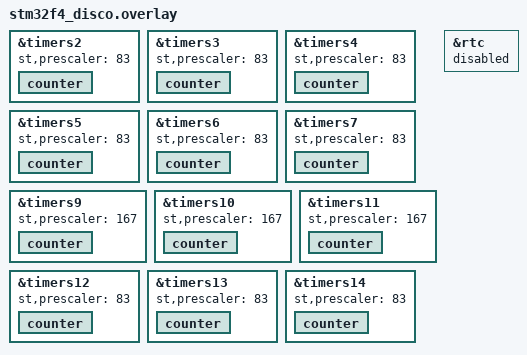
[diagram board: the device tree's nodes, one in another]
/*
 * Copyright (c) 2025 STMicroelectronics
 *
 * SPDX-License-Identifier: Apache-2.0
 */

&timers2 {
	st,prescaler = <83>;
	status = "okay";

	counter {
		status = "okay";
	};
};

&timers3 {
	st,prescaler = <83>;
	status = "okay";

	counter {
		status = "okay";
	};
};

&timers4 {
	st,prescaler = <83>;
	status = "okay";

	counter {
		status = "okay";
	};
};

&timers5 {
	st,prescaler = <83>;
	status = "okay";

	counter {
		status = "okay";
	};
};

&timers6 {
	st,prescaler = <83>;
	status = "okay";

	counter {
		status = "okay";
	};
};

&timers7 {
	st,prescaler = <83>;
	status = "okay";

	counter {
		status = "okay";
	};
};

&timers9 {
	st,prescaler = <167>;
	status = "okay";

	counter {
		status = "okay";
	};
};

&timers10 {
	st,prescaler = <167>;
	status = "okay";

	counter {
		status = "okay";
	};
};

&timers11 {
	st,prescaler = <167>;
	status = "okay";

	counter {
		status = "okay";
	};
};

&timers12 {
	st,prescaler = <83>;
	status = "okay";

	counter {
		status = "okay";
	};
};

&timers13 {
	st,prescaler = <83>;
	status = "okay";

	counter {
		status = "okay";
	};
};

&timers14 {
	st,prescaler = <83>;
	status = "okay";

	counter {
		status = "okay";
	};
};

&rtc {
	status = "disabled";
};
